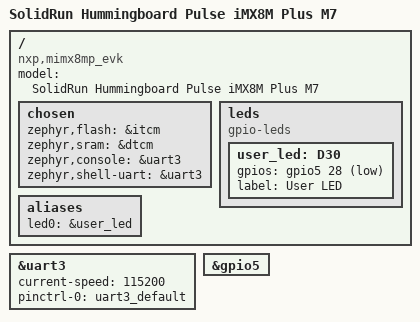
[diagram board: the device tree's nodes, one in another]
/dts-v1/;

#include <nxp/nxp_imx8ml_m7.dtsi>
#include "hummingboard_pulse_imx8mp-pinctrl.dtsi"
#include <zephyr/dt-bindings/gpio/gpio.h>

/ {
	model = "SolidRun Hummingboard Pulse iMX8M Plus M7";
	compatible = "nxp,mimx8mp_evk";

	chosen {
		/* TCM */
		zephyr,flash = &itcm;
		zephyr,sram = &dtcm;

		zephyr,console = &uart3;
		zephyr,shell-uart = &uart3;

		/* zephyr,ipc_shm = &sram_shm;
		zephyr,ipc = &mailbox0; */
	};

	/* Addr & Size to verify */
	/* sram_shm: memory@55000000 {
		compatible = "mmio-sram";
		reg = <0x55000000 0x8000>;
	}; */

	leds {
		compatible = "gpio-leds";

		user_led: D30 {
			gpios = <&gpio5 28 GPIO_ACTIVE_LOW>;
			label = "User LED";
		};
	};

	aliases {
		led0 = &user_led;
	};

};

/* mikrobus uart */
&uart3 {
	status = "okay";
	current-speed = <115200>;
	pinctrl-0 = <&uart3_default>;
	pinctrl-names = "default";
};

&gpio5 {
	status = "okay";
};

/* &mailbox0 {
	status = "okay";
}; */
